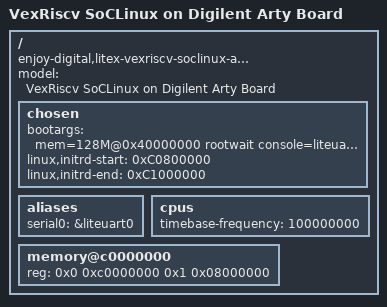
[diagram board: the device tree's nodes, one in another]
/include/ "litex-vexriscv-linux.dtsi"

/ {
	compatible = "enjoy-digital,litex-vexriscv-soclinux-arty", "enjoy-digital,litex-vexriscv-soclinux";
	model = "VexRiscv SoCLinux on Digilent Arty Board";

	chosen {
		bootargs = "mem=128M@0x40000000 rootwait console=liteuart root=/dev/ram0 init=/sbin/init swiotlb=32";
		linux,initrd-start = <0xC0800000>;
		linux,initrd-end   = <0xC1000000>; // max 8MB ramdisk image
	};

	aliases {
		serial0 = &liteuart0;
	};

	cpus {
		timebase-frequency = <100000000>;
	};

	memory@c0000000 {
		device_type = "memory";
		reg = <0x0 0xc0000000 0x1 0x08000000>;
	};
};
